# MKE04Z1284 register map
Vendor: Freescale Semiconductor, Inc.; Series: Kinetis_E; File version: 1.6
CPU: CM0PLUS r0p0, little endian, no MPU, no FPU, VTOR, 2 interrupt priority bits
Registers are 32-bit, read-write, reset 0x0 unless marked. A register's access mark holds for its fields unless they carry their own. Offsets are from the block's base; [hi:lo] are bit positions; {n}, {i} and the like mark numbered series; 'fields as' and 'values as' point back to an identical list.

## FTMRE_FlashConfig — Flash configuration field
Base 0x00000400; register names take the prefix NV_
{0x0+i} BACKKEY{i} 8-bit ro reset 0xFF (i=0..7) — Backdoor Comparison Key {i}
  [7:0] KEY — Backdoor Comparison Key.
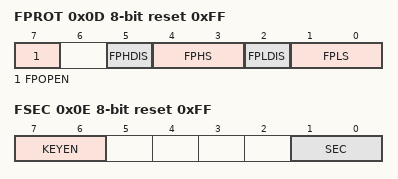
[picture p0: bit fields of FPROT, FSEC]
0x0D FPROT 8-bit ro reset 0xFF — Non-volatile P-Flash Protection Register
  [7] FPOPEN
    0=FPHDIS and FPLDIS bits define unprotected address ranges as specified by the corresponding FPHS and FPLS bits FPROT1.1; 1=FPHDIS and FPLDIS bits enable protection for the address range specified by the corresponding FPHS and FPLS bits
  [5] FPHDIS
    0=Protection/Unprotection enabled; 1=Protection/Unprotection disabled
  [4:3] FPHS
    0=Address range: 0x00_7C00-0x00_7FFF; protected size: 1 KB; 1=Address range: 0x00_7800-0x00_7FFF; protected size: 2 KB; 2=Address range: 0x00_7000-0x00_7FFF; protected size: 4 KB; 3=Address range: 0x00_6000-0x00_7FFF; protected size: 8 KB
  [2] FPLDIS
    values as FPHDIS
  [1:0] FPLS
    0=Address range: 0x00_0000-0x00_07FF; protected size: 2 KB; 1=Address range: 0x00_0000-0x00_0FFF; protected size: 4 KB; 2=Address range: 0x00_0000-0x00_1FFF; protected size: 8 KB; 3=Address range: 0x00_0000-0x00_3FFF; protected size: 16 KB
0x0E FSEC 8-bit ro reset 0xFF — Non-volatile Flash Security Register
  [7:6] KEYEN — Backdoor Key Security Enable
    2=Backdoor key access enabled; 3=Backdoor key access disabled
  [1:0] SEC — Flash Security
    2=MCU security status is unsecure; 3=MCU security status is secure
0x0F FOPT 8-bit ro reset 0xFF — Non-volatile Flash Option Register

## FTMRE — Flash Memory
Base 0x40020000; register names take the prefix FTMRE_
0x01 FCCOBIX 8-bit — Flash CCOB Index Register
  [2:0] CCOBIX — Common Command Register Index
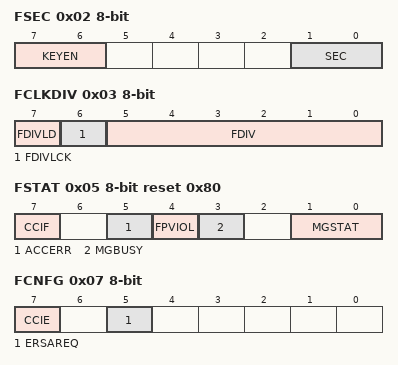
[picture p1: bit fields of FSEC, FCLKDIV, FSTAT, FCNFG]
0x02 FSEC 8-bit ro reset not defined — Flash Security Register
  [7:6] KEYEN — Backdoor Key Security Enable Bits
    0=Disabled; 1=Disabled; 2=Enabled; 3=Disabled
  [1:0] SEC — Flash Security Bits
    0=Secured; 1=Secured; 2=Unsecured; 3=Secured
0x03 FCLKDIV 8-bit — Flash Clock Divider Register
  [7] FDIVLD ro — Clock Divider Loaded
    0=FCLKDIV register has not been written since the last reset; 1=FCLKDIV register has been written since the last reset
  [6] FDIVLCK — Clock Divider Locked
    0=FDIV field is open for writing; 1=FDIV value is locked and cannot be changed. After the lock bit is set high, only reset can clear this bit and restore writability to the FDIV field in user mode.
  [5:0] FDIV — Clock Divider Bits
0x05 FSTAT 8-bit reset 0x80 — Flash Status Register
  [7] CCIF — Command Complete Interrupt Flag
    0=Flash command is in progress; 1=Flash command has completed
  [5] ACCERR — Flash Access Error Flag
    0=No access error is detected; 1=Access error is detected
  [4] FPVIOL — Flash Protection Violation Flag
    0=No protection violation is detected; 1=Protection violation is detected
  [3] MGBUSY ro — Memory Controller Busy Flag
    0=Memory controller is idle; 1=Memory controller is busy executing a flash command (CCIF = 0)
  [1:0] MGSTAT ro — Memory Controller Command Completion Status Flag
0x07 FCNFG 8-bit — Flash Configuration Register
  [7] CCIE — Command Complete Interrupt Enable
    0=Command complete interrupt is disabled; 1=An interrupt will be requested whenever the CCIF flag in the FSTAT register is set
  [5] ERSAREQ ro — Debugger Mass Erase Request
    0=No request or request complete; 1=Request to run the Erase All Blocks command verify the erased state program the security byte in the Flash Configuration Field to the unsecure state release MCU security by setting FSEC[SEC] to the unsecure state
0x08 FCCOBLO 8-bit — Flash Common Command Object Register: Low
  [7:0] CCOB — Common Command Object Bit 7:0
0x09 FCCOBHI 8-bit — Flash Common Command Object Register:High
  [7:0] CCOB — Common Command Object Bit 15:8
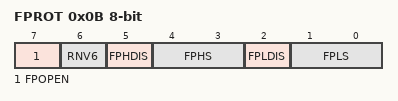
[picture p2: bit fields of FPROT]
0x0B FPROT 8-bit reset not defined — Flash Protection Register
  [7] FPOPEN — Flash Protection Operation Enable
    0=When FPOPEN is clear, the FPHDIS and FPLDIS fields define unprotected address ranges as specified by the corresponding FPHS and FPLS fields; 1=When FPOPEN is set, the FPHDIS and FPLDIS fields enable protection for the address range specified by the corresponding FPHS and FPLS fields
  [6] RNV6 ro — Reserved Nonvolatile Bit
  [5] FPHDIS — Flash Protection Higher Address Range Disable
    0=Protection/Unprotection enabled; 1=Protection/Unprotection disabled
  [4:3] FPHS — Flash Protection Higher Address Size
  [2] FPLDIS — Flash Protection Lower Address Range Disable
    values as FPHDIS
  [1:0] FPLS — Flash Protection Lower Address Size
0x0F FOPT 8-bit ro reset not defined — Flash Option Register
  [7:0] NV — Nonvolatile Bits

## Notices in the file
Redistribution and use in source and binary forms, with or without modification,
are permitted provided that the following conditions are met:
o Redistributions of source code must retain the above copyright notice, this list
of conditions and the following disclaimer.
o Redistributions in binary form must reproduce the above copyright notice, this
list of conditions and the following disclaimer in the documentation and/or
other materials provided with the distribution.
o Neither the name of Freescale Semiconductor, Inc. nor the names of its
contributors may be used to endorse or promote products derived from this
software without specific prior written permission.
THIS SOFTWARE IS PROVIDED BY THE COPYRIGHT HOLDERS AND CONTRIBUTORS "AS IS" AND
ANY EXPRESS OR IMPLIED WARRANTIES, INCLUDING, BUT NOT LIMITED TO, THE IMPLIED
WARRANTIES OF MERCHANTABILITY AND FITNESS FOR A PARTICULAR PURPOSE ARE
DISCLAIMED. IN NO EVENT SHALL THE COPYRIGHT HOLDER OR CONTRIBUTORS BE LIABLE FOR
ANY DIRECT, INDIRECT, INCIDENTAL, SPECIAL, EXEMPLARY, OR CONSEQUENTIAL DAMAGES
(INCLUDING, BUT NOT LIMITED TO, PROCUREMENT OF SUBSTITUTE GOODS OR SERVICES;
LOSS OF USE, DATA, OR PROFITS; OR BUSINESS INTERRUPTION) HOWEVER CAUSED AND ON
ANY THEORY OF LIABILITY, WHETHER IN CONTRACT, STRICT LIABILITY, OR TORT
(INCLUDING NEGLIGENCE OR OTHERWISE) ARISING IN ANY WAY OUT OF THE USE OF THIS
SOFTWARE, EVEN IF ADVISED OF THE POSSIBILITY OF SUCH DAMAGE.
